# RN831X_RN861X_MCU register map
File version: v0.0.1
CPU: RN831X_RN861X_MCU r1p0, little endian, MPU, no FPU
Registers are 32-bit, read-write, reset 0x0 unless marked. A register's access mark holds for its fields unless they carry their own. Offsets are from the block's base; [hi:lo] are bit positions; {n}, {i} and the like mark numbered series.

## SEA_CORE0
Base 0x30008000
Same registers: SEA_CORE1 0xB0008000
0x100 START — SEA Start Register.
  [0] EN — Start SEA running
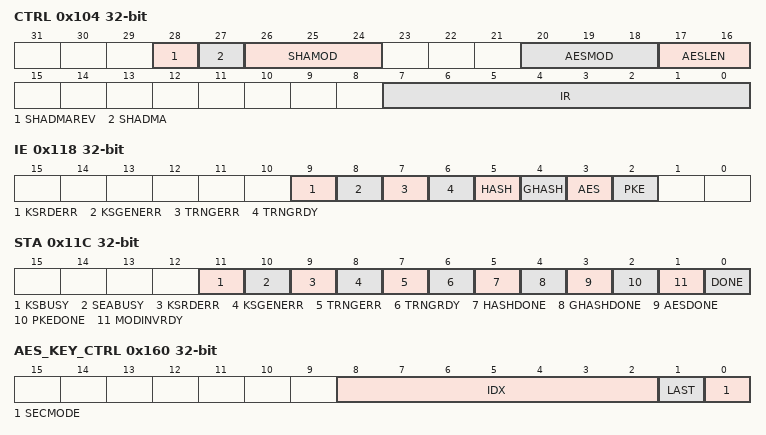
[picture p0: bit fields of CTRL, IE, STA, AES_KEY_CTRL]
0x104 CTRL — SEA Control Register.
  [28] SHADMAREV — Enable HASH DMA reverse input in byte.
  [27] SHADMA — Enable HASH DMA.
  [26:24] SHAMOD — Set HASH calculation mode.
    0=SHA1 (SHA1 mode.); 1=SHA224 (SHA224 mode.); 2=SHA256 (SHA256 mode.); 4=SHA384 (SHA384 mode.); 5=SHA512 (SHA512 mode.)
  [20:18] AESMOD — Set AES data stream mode.
    0=ECB (AES ECB mode.); 1=CBC (AES CBC mode.); 2=CTR (AES CTR mode.); 3=CFB128 (AES CFB128 mode.); 4=OFB (AES OFB mode.)
  [17:16] AESLEN — Set AES key length.
    0=KELN128 (128-bit key.); 1=KLEN192 (192-bit key.); 2=KLEN256 (256-bit key.)
  [7:0] IR — Set different calculation methods.
    1=ECC_H (Start calculating H in ECC); 2=ECC_MODMULT (Start Modular Exponentiation in ECC); 3=ECC_ADD_I2M (ADD I2M); 4=ECC_DBL_I2M (DBL I2M); 5=ECC_POINT_ADD (Point Addition); 6=ECC_POINT_DBL (Point Double); 7=ECC_M2I (M2I); 8=ECC_MODINV (Modular Inversion); 9=ECC_MODADD (Modular Addition); 10=ECC_MODSUB (Moduar Subtraction); 17=RSA_H (Get H); 18=RSA_MODMULT (Modular Multiplication); 19=RSA_MODEXP (Modular Exponentiation); 32=J0 (Get J0); 64=AES_KEYEXP (AES expend key); 66=AES_ENC (AES encryption); 67=AES_DEC (AES decryption); 128=AES_GF128 (AES GF128 operation); 144=SHA0 (SHA1/SHA224/256); 145=SHA1 (SHA384/SHA512)
0x108 N0LOW — SEA FIPS Parameter Register 0.
  [31:0] VAL — The low 32bits of Modular N
0x10C N0HIGH — SEA FIPS Parameter Register 1.
  [31:0] VAL — The high 32bits of Modular N
0x110 NLEN — SEA Module Length Register.
  [11:0] LEN — The bit length of Modular N
0x114 ELEN — SEA Power Length Register.
  [11:0] LEN — The bit length of Power E
0x118 IE — SEA Interrupt Enable Register.
  [9] KSRDERR — Enabel fail to read key from Keystore interrupt.
  [8] KSGENERR — Enabel store key generated by TRNG to Keystore error interrupt.
  [7] TRNGERR — Enable TRNG random number detecion error interrupt.
  [6] TRNGRDY — Enable TRNG data ready interrupt.
  [5] HASH — Enable HASH finish interrupt.
  [4] GHASH — Enable GHASH finish interrupt.
  [3] AES — Enable AES finish interrupt.
  [2] PKE — Enable ECC and RSA finish interrupt.
0x11C STA — SEA Status Register.
  [11] KSBUSY — Keystore Module busy.
  [10] SEABUSY — SEA Module busy.
  [9] KSRDERR — Keystore read key interrupt flag.
  [8] KSGENERR — Keystore write key interrupt flag.
  [7] TRNGERR — TRNG random error interrupt flag.
  [6] TRNGRDY — TRNG data ready pending interrupt flag.
  [5] HASHDONE — HASH calculations completed flag.
  [4] GHASHDONE — GHASH calculations completed flag.
  [3] AESDONE — AES calculations completed flag.
  [2] PKEDONE — ECC and RSA calculations completed flag.
  [1] MODINVRDY — Modular Inversion operation can be possible.
  [0] DONE — SEA calculations completed flag.
{0x120+4i} GHASH_X{i} (i=0..3) — 128-bit GHASH Multiplicand X Registers.
  [31:0] X0 — The Multplicand X of GHASH
{0x130+4i} GHASH_Y{i} (i=0..3) — 128-bit GHASH Multiplier Y Registers.
  [31:0] Y0 — The Multiplier Y of GHASH
{0x140+4i} GHASH_Z{i} (i=0..3) — 128-bit GHASH Result Z Registers.
  [31:0] Z0 — The Result Z of GHASH
{0x150+4i} IV{i} (i=0..3) — SEA IVector Registers.
  [31:0] IV0 — AES IV buffer0
0x160 AES_KEY_CTRL — AES Key Control Register.
  [8:2] IDX — AES key index in KeyStore.
  [1] LAST — AES last calculation flag.
  [0] SECMODE — Enable AES secure mode.
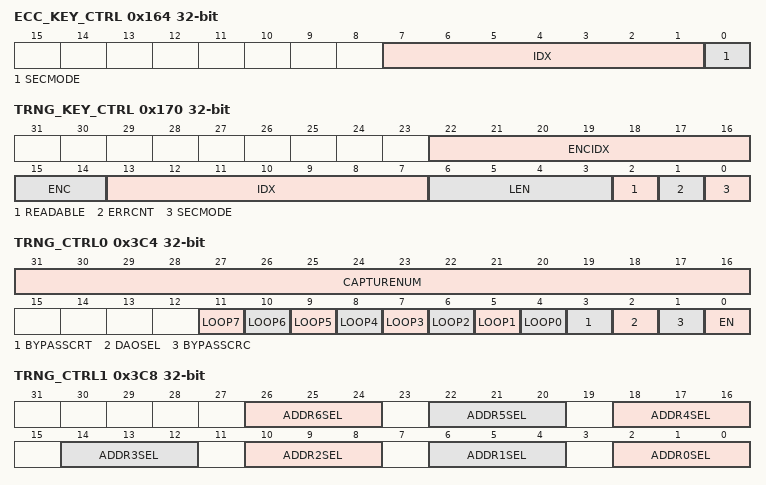
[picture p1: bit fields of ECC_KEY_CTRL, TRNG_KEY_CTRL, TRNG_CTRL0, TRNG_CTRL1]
0x164 ECC_KEY_CTRL — ECC Key Control Register.
  [7:1] IDX — ECC key<x> index in KeyStore.
  [0] SECMODE — Enable ECC secure mode.
0x168 HASH_DMA_IDATA — HASH DMA Input Data Register.
  [31:0] DATA — DMA Input Data
0x16C HASH_DMA_STA ro — HASH DMA Status Register.
  [4:0] CNT — DMA Status
0x170 TRNG_KEY_CTRL — TRNG Key Control Register.
  [22:16] ENCIDX — Set key index to encrypt current key.
  [15:14] ENC — Enable key encrypted store in KeyStore.
  [13:7] IDX — Set key index.
  [6:3] LEN — Set key length.
  [2] READABLE — Set key is readable to CPU.
  [1] ERRCNT — Still generate key with random error.
  [0] SECMODE — Enable TRNG secure mode.
0x3C4 TRNG_CTRL0 — TRNG Control Register 0.
  [31:16] CAPTURENUM — Defines random number sampling.
  [n+4] LOOP{n} (n=0..7) — Enable Ring vibration loop {n}.
  [3] BYPASSCRT — Enable Error correction algorithm.
  [2] DAOSEL — Selet the interleaving algorithm.
  [1] BYPASSCRC — Enable CRC or BypassCRC.
  [0] EN — Enable TRNG calculation.
0x3C8 TRNG_CTRL1 — TRNG Control Register 1.
  [4n+2:4n] ADDR{n}SEL (n=0..6) — Select Bit{n} to interweave new address.
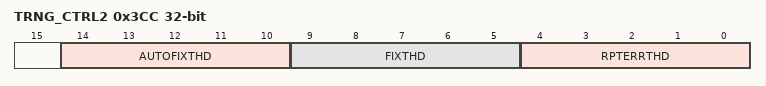
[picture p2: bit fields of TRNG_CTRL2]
0x3CC TRNG_CTRL2 — TRNG Control Register 2.
  [14:10] AUTOFIXTHD — Error correction starts when the number of detection cycle errors >= the number of error corrections.
  [9:5] FIXTHD — Error correction starts when the number of detection cycle errors >= the number of configured threshold.
  [4:0] RPTERRTHD — Error correction starts when the number of detection cycle errors >= the number of automatic error corrections.
0x3D0 TRNG_STA — TRNG Status Register.
  [4:0] ERRNUM — TRNG Status
{0x3D4+4i} TRNG_BUF{i} (i=0..3) — TRNG Buffer Registers.
  [31:0] BUF0 — TRNG Buffer
